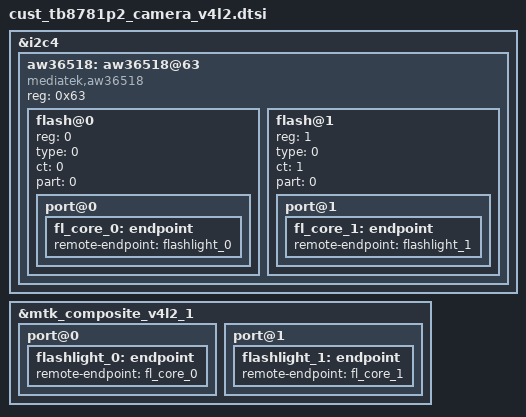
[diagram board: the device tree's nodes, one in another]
// SPDX-License-Identifier: GPL-2.0
/* Copyright (c) 2020 MediaTek Inc. */

&i2c4 {
	aw36518:aw36518@63 {
		compatible = "mediatek,aw36518";
		reg = <0x63>;
		status = "okay";
		flash@0{
			reg = <0>;
			type = <0>;
			ct = <0>;
			part = <0>;
			port@0 {
				fl_core_0: endpoint {
					remote-endpoint = <&flashlight_0>;
				};
			};
		};
		flash@1{
			reg = <1>;
			type = <0>;
			ct = <1>;
			part = <0>;
			port@1 {
				fl_core_1: endpoint {
					remote-endpoint = <&flashlight_1>;
				};
			};
		};
	};
};

&mtk_composite_v4l2_1 {
	port@0 {
		flashlight_0: endpoint {
			remote-endpoint = <&fl_core_0>;
		};
	};
	port@1 {
		flashlight_1: endpoint {
			remote-endpoint = <&fl_core_1>;
		};
	};
};
